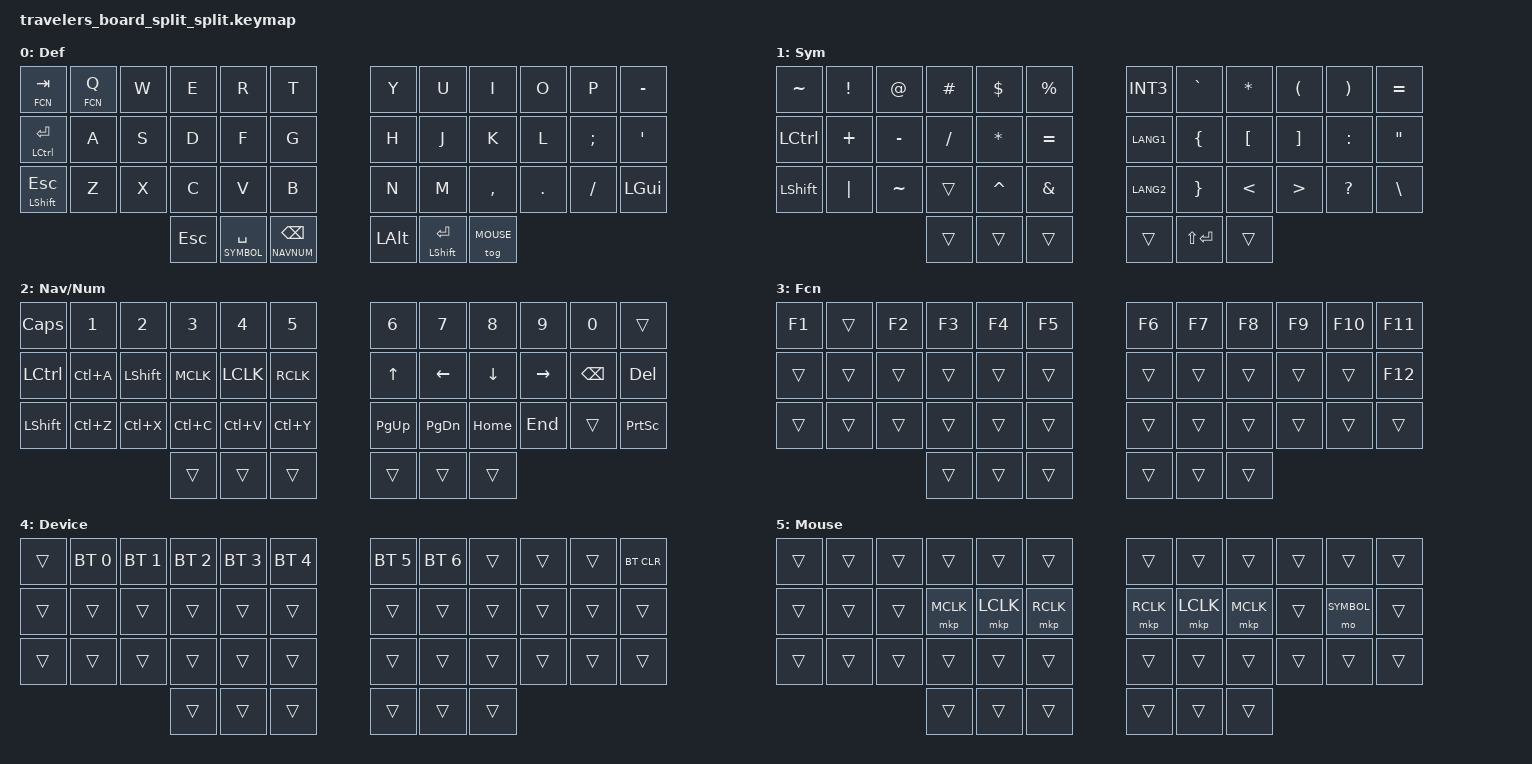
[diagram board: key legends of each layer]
#include <behaviors.dtsi>
#include <behaviors/jp.dtsi>
#include <dt-bindings/zmk/bt.h>
#include <dt-bindings/zmk/keys.h>
#include <dt-bindings/zmk/pointing.h>

/*
 * Derived from the Modula keymap. Travelers has 42 physical positions rather
 * than Modula's 58: the unavailable positions, encoders, and pointing
 * device bindings are represented by standard keyboard equivalents.
 */
#define DEFAULT 0
#define SYMBOL 1
#define NAVNUM 2
#define FCN 3
#define DEVICE 4
#define MOUSE 5

&mt {
    flavor = "hold-preferred";
};

&lt {
    flavor = "hold-preferred";
};

/ {
    conditional_layers {
        compatible = "zmk,conditional-layers";

        device_layer {
            if-layers = <SYMBOL NAVNUM>;
            then-layer = <DEVICE>;
        };
    };

    behaviors {
        /* Modula-compatible hold-tap behavior definitions. */
        plt: positional_layer_tap {
            compatible = "zmk,behavior-hold-tap";
            #binding-cells = <2>;
            flavor = "hold-preferred";
            tapping-term-ms = <1000>;
            quick-tap-ms = <200>;
            bindings = <&mo>, <&kp>;
            hold-trigger-key-positions = <0>;
        };

        mth: mt_hold_while_undecided {
            compatible = "zmk,behavior-hold-tap";
            #binding-cells = <2>;
            flavor = "hold-preferred";
            hold-while-undecided;
            tapping-term-ms = <200>;
            bindings = <&kp>, <&kp>;
        };

        lth: lt_hold_while_undecided {
            compatible = "zmk,behavior-hold-tap";
            #binding-cells = <2>;
            flavor = "hold-preferred";
            hold-while-undecided;
            tapping-term-ms = <200>;
            bindings = <&mo>, <&kp>;
        };

        mtt: mt_tap_preferred {
            compatible = "zmk,behavior-hold-tap";
            #binding-cells = <2>;
            flavor = "tap-preferred";
            tapping-term-ms = <150>;
            quick-tap-ms = <0>;
            bindings = <&kp>, <&kp>;
        };

        ltt: lt_tap_preferred {
            compatible = "zmk,behavior-hold-tap";
            #binding-cells = <2>;
            flavor = "tap-preferred";
            tapping-term-ms = <200>;
            bindings = <&mo>, <&kp>;
        };
    };

    keymap {
        compatible = "zmk,keymap";

        default_layer {
            label = "Def";
            bindings = <
                &lth FCN TAB    &plt FCN Q    &kp W       &kp E     &kp R           &kp T       &kp Y       &kp U           &kp I       &kp O       &kp P        &kp MINUS
                &mth LCTRL RET  &kp A          &kp S       &kp D     &kp F           &kp G       &kp H       &kp J           &kp K       &kp L       &kp SEMI     &kp SQT
                &mth LSHIFT ESC &kp Z          &kp X       &kp C     &kp V           &kp B       &kp N       &kp M           &kp COMMA   &kp DOT     &kp SLASH    &kp LGUI
                &kp ESC         &lth SYMBOL SPACE &lth NAVNUM BSPC &kp LALT &mth LSHIFT RET &tog MOUSE
            >;
        };

        symbol_layer {
            label = "Sym";
            bindings = <
                &kp TILDE       &kp EXCL       &kp AT      &kp HASH  &kp DLLR        &kp PRCNT   &kp INT3    &kp GRAVE       &kp ASTRK   &kp LPAR    &kp RPAR    &kp EQUAL
                &kp LCTRL       &kp PLUS       &kp MINUS   &kp SLASH &kp ASTRK       &kp EQUAL   &kp LANG1   &kp LBRC        &kp LBKT    &kp RBKT    &kp COLON   &kp DQT
                &kp LSHIFT      &kp PIPE       &kp TILDE   &trans    &kp CARET       &kp AMPS    &kp LANG2   &kp RBRC        &kp LT      &kp GT      &kp QMARK   &kp BSLH
                &trans          &trans         &trans      &trans    &kp LS(RET)     &trans
            >;
        };

        navnum_layer {
            label = "Nav/Num";
            bindings = <
                &kp CAPSLOCK    &kp N1         &kp N2      &kp N3   &kp N4          &kp N5      &kp N6      &kp N7          &kp N8      &kp N9      &kp N0      &trans
                &kp LCTRL       &kp LC(A)      &kp LSHIFT  &kp MCLK &kp LCLK        &kp RCLK    &kp UP      &kp LEFT        &kp DOWN    &kp RIGHT   &kp BSPC    &kp DEL
                &kp LSHIFT      &kp LC(Z)      &kp LC(X)   &kp LC(C)&kp LC(V)       &kp LC(Y)   &kp PG_UP   &kp PG_DN       &kp HOME    &kp END     &trans      &kp PSCRN
                &trans          &trans         &trans      &trans   &trans          &trans
            >;
        };

        function_layer {
            label = "Fcn";
            bindings = <
                &kp F1          &trans         &kp F2      &kp F3   &kp F4          &kp F5      &kp F6      &kp F7          &kp F8      &kp F9      &kp F10     &kp F11
                &trans          &trans         &trans      &trans   &trans          &trans      &trans      &trans          &trans      &trans      &trans      &kp F12
                &trans          &trans         &trans      &trans   &trans          &trans      &trans      &trans          &trans      &trans      &trans      &trans
                &trans          &trans         &trans      &trans   &trans          &trans
            >;
        };

        device_layer {
            label = "Device";
            bindings = <
                &trans          &bt BT_SEL 0   &bt BT_SEL 1 &bt BT_SEL 2 &bt BT_SEL 3 &bt BT_SEL 4 &bt BT_SEL 5 &bt BT_SEL 6 &trans &trans &trans &bt BT_CLR
                &trans          &trans         &trans       &trans       &trans       &trans       &trans       &trans       &trans &trans &trans &trans
                &trans          &trans         &trans       &trans       &trans       &trans       &trans       &trans       &trans &trans &trans &trans
                &trans          &trans         &trans       &trans       &trans       &trans
            >;
        };

        mouse_layer {
            label = "Mouse";
            bindings = <
                &trans          &trans         &trans       &trans       &trans       &trans       &trans       &trans       &trans &trans &trans &trans
                &trans          &trans         &trans       &mkp MCLK    &mkp LCLK    &mkp RCLK    &mkp RCLK    &mkp LCLK    &mkp MCLK &trans &mo SYMBOL &trans
                &trans          &trans         &trans       &trans       &trans       &trans       &trans       &trans       &trans &trans &trans &trans
                &trans          &trans         &trans       &trans       &trans       &trans
            >;
        };
    };
};
